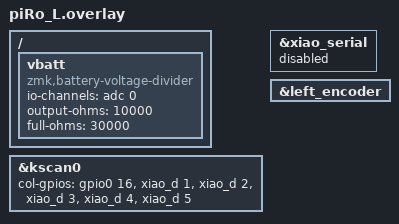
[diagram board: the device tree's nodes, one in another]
#include "piRo.dtsi"

&kscan0 {
        col-gpios
            //= <&xiao_d 0 GPIO_ACTIVE_HIGH>
            = <&gpio0 16 GPIO_ACTIVE_HIGH>
            , <&xiao_d 1 GPIO_ACTIVE_HIGH> 
            , <&xiao_d 2 GPIO_ACTIVE_HIGH> 
            , <&xiao_d 3 GPIO_ACTIVE_HIGH> 
            , <&xiao_d 4 GPIO_ACTIVE_HIGH>
            , <&xiao_d 5 GPIO_ACTIVE_HIGH>
            ;
};

&xiao_serial { status = "disabled"; };

&left_encoder {
    status = "okay";
};

/ {
    vbatt: vbatt {
        compatible = "zmk,battery-voltage-divider";
        io-channels = <&adc 0>;
        output-ohms = <10000>;
        full-ohms   = <30000>;
    };
};
